# DEBUGSS_WRAP_PWRAP_CFG_1_000740002300h register map
Vendor: Texas Instruments
Peripheral module from a debugger description file (folder am62D).
Registers are 32-bit, access not given, reset values left out (the file's numbers can be read two ways) unless marked. A register's access mark holds for its fields unless they carry their own. Offsets are as the file gives them; lines under a group give offsets from that group; [hi:lo] are bit positions; {n}, {i} and the like mark numbered series; 'fields as' and 'values as' point back to an identical list; <NAME> marks a mode.

## pwrap_cfg_1
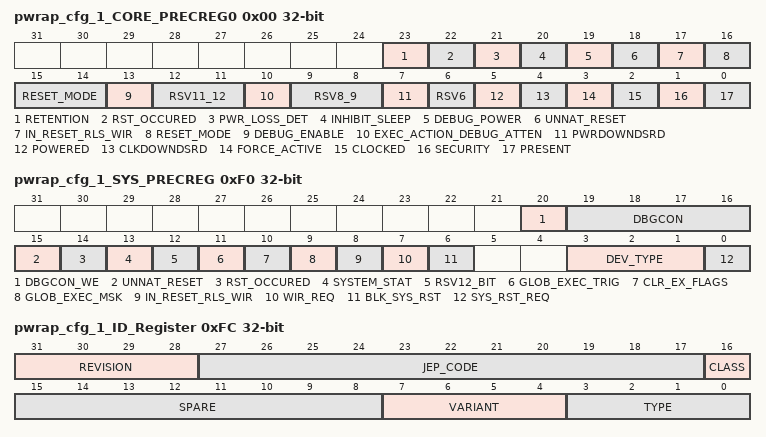
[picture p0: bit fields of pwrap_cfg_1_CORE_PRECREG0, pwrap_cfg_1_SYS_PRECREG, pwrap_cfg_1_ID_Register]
0x00 pwrap_cfg_1_CORE_PRECREG0 access per field — These registers are used to control functionality of CPUs without JTAG ports. There can be upto 32 of these registers
  [23] RETENTION ro — Core is in retention mode
  [22] RST_OCCURED rw — Sticky bit indicating a reset has occured Write 1 to clear this bit
  [21] PWR_LOSS_DET rw — Power Loss Detected Sticky bit, write a 1 to clear this bit
  [20] INHIBIT_SLEEP rw — Inhinit Sleep Block core from entering sleep mode
  [19] DEBUG_POWER rw — Core debug logic is powered
  [18] UNNAT_RESET ro — Unnatural Reset Device reset state is being affected by debug logic
  [17] IN_RESET_RLS_WIR rw — Writing a 1 releases the WIR When read this returns the reset status, 1 indicates core is in reset
  [16:14] RESET_MODE rw — Reset Mode 0=normal, 1=WIR, 2=Blk Rst, 3=Blk Assert, 4=Halt on Rst, 5=Cancel, 6=Halt and Block, 7=Halt-Blk-assert
  [13] DEBUG_ENABLE rw — Debug Enabled signal to the core
  [12:11] RSV11_12 ro — Reserved, return 0
  [10] EXEC_ACTION_DEBUG_ATTEN rw — Writing this bit causes Execution Read will return the Debug Attention input value
  [9:8] RSV8_9 ro — Reserved, returns 0 when read
  [7] PWRDOWNDSRD ro — The core wants to turn off it's power when high
  [6] RSV6 ro — Reserved, returns 0 when read
  [5] POWERED ro — Core is powered up when high
  [4] CLKDOWNDSRD ro — The core wants to turn off it's clock when high
  [3] FORCE_ACTIVE rw — Force core active Turn on power and clocks
  [2] CLOCKED ro — When high the core clock is active
  [1] SECURITY ro — Security bit When high security is allowing access
  [0] PRESENT ro — The core controlled by this register exists when 1
{0x0+4i} pwrap_cfg_1_CORE_PRECREG{i} (i=1..31) — These registers are used to control functionality of CPUs without JTAG ports. See CORE_PRECREG0 for details
0xF0 pwrap_cfg_1_SYS_PRECREG access per field — This register is used to control system level functionality
  [20] DBGCON_WE rw — This bit must be high to write to the debug connect field
  [19:16] DBGCON rw — The system debugger must write a value of 0x9 to be connected and access the debug logic
  [15] UNNAT_RESET ro — Unnatural Reset Device reset state is being affected by debug logic
  [14] RST_OCCURED rw — Sticky bit indicating a reset has occured Write 1 to clear this bit
  [13] SYSTEM_STAT ro — System Status input, application specificall
  [12] RSV12_BIT ro — Reserved, read returns 0
  [11] GLOB_EXEC_TRIG ro
  [10] CLR_EX_FLAGS rw — Clear all run flags
  [9] GLOB_EXEC_MSK rw — Global Execute Mask
  [8] IN_RESET_RLS_WIR rw — Writing a 1 releases the global WIR When read this returns the in reset status
  [7] WIR_REQ rw — Wait In Reset Request
  [6] BLK_SYS_RST rw — Block System Reset
  [3:1] DEV_TYPE ro — Device Type tieoff value Test, emulator, secure, etc
  [0] SYS_RST_REQ rw — System Reset Request This bit will be reset once reset occurs
0xFC pwrap_cfg_1_ID_Register ro — Reading this register returns the ID information for this AP.
  [31:28] REVISION — Device Revision [0]
  [27:17] JEP_CODE — Device JEP Code [0x017]
  [16] CLASS — Device Class[1] [a memory access port]
  [15:8] SPARE — Spare, returns 0
  [7:4] VARIANT — Device Variant [0]
  [3:0] TYPE — Device Type: 0=JTAG, 1=AHB, 2=APB [2]
